# LPC11Axx register map
File version: 0.6
CPU: CM0 r0p0, little endian, no MPU, no FPU, 2 interrupt priority bits
Registers are 32-bit, read-write, reset 0x0 unless marked. A register's access mark holds for its fields unless they carry their own. Offsets are from the block's base; lines under a group give offsets from that group; [hi:lo] are bit positions; {n}, {i} and the like mark numbered series; 'fields as' and 'values as' point back to an identical list; <NAME> marks a mode.

## Memory map
0x40000000 I2C size 0x1000 — I2C-bus controller
0x40004000 WWDT size 0x1000 — Windowed Watchdog Timer (WWDT)
0x40008000 USART size 0x1000
0x4000C000 CT16B0 size 0x1000 — 16-bit counter/timers CT16B0/1
0x40010000 CT16B1 size 0x1000
0x40014000 CT32B0 size 0x1000 — 32-bit counter/timers CT32B0/1
0x40018000 CT32B1 size 0x1000
0x4001C000 ADC size 0x1000
0x40024000 DAC size 0x1000
0x40028000 CMP size 0x1000 — Comparator
0x4003C000 FMC size 0x1000 — Flash controller
0x40040000 SSP0 size 0x1000 — SSP/SPI
0x40044000 IOCON size 0x1000 — IOCON block
0x40048000 SYSCON size 0x1000 — System configuration
0x4004C000 GPIO_PIN_INT size 0x1000 — GPIO Modification
0x40058000 SSP1 size 0x1000
0x4005C000 GPIO_GROUP_INT0 size 0x1000 — GPIO group interrupt
0x40060000 GPIO_GROUP_INT1 size 0x1000
0x50000000 GPIO_PORT size 0x4000

## Interrupts
{n} PIN_INT{n} (GPIO_PIN_INT) (n=0..7)
8 GINT0 (GPIO_GROUP_INT0)
9 GINT1 (GPIO_GROUP_INT1)
10 CMP
11 DAC
12 RESERVED0 (SYSCON)
13 RESERVED1 (SYSCON)
14 SSP1
15 I2C
16 CT16B0
17 CT16B1
18 CT32B0
19 CT32B1
20 SSP0
21 USART
22 RESERVED2 (SYSCON)
23 RESERVED3 (SYSCON)
24 ADC
25 WDT (WWDT)
26 BOD (SYSCON)
27 FMC
28 RESERVED4 (SYSCON)
29 RESERVED5 (SYSCON)
30 RESERVED6 (SYSCON)
31 RESERVED7 (SYSCON)

## DAC
Base 0x40024000
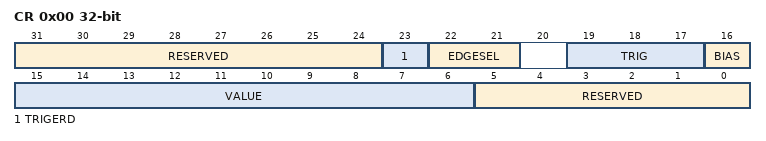
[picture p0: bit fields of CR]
0x00 CR — D/A control register
  [31:24] RESERVED — Reserved, user software should not write ones to reserved bits. The value read from a reserved bit is not defined.
  [23] TRIGERD — If the TRIG field (above) is non-zero, this bit is set when a conversion is triggered, and is cleared by any write to this register.
  [22:21] EDGESEL — For non-zero values of TRIG, this field selects when the conversion is triggered:
    0=FALLING (Falling edges); 1=RISINGs (Rising edges); 2=DUALEDGE (Both edges); 3=DUALEDGE (Both edges)
  [19:17] TRIG — The value written to this field determines whether conversion begins immediately after this register is written, or whether conversion is delayed until a selected event occurs.
    0=IMMEDIATE (Conversion begins when this register is written, and AOUT begins to change to the new voltage immediately. For all other values in this field, AOUT remains at its previous voltage until the selected event has occurred.); 1=COMPLEVELOUT (Conversion is triggered by the selected edge(s) on the analog comparator (level) output); 2=ATRG0EDGE (Conversion is triggered by the selected edge(s) on ATRG0.); 3=ATRG1EDGE (Conversion is triggered by the selected edge(s) on ATRG1.); 4=CT32B1_MAT0EDGE (Conversion is triggered by the selected edge(s) on CT32B1_MAT0 [2].); 5=CT32B1_MAT1EDGE (Conversion is triggered by the selected edge(s) on CT32B1_MAT1[2].); 6=CT16B1_MAT0EDGE (Conversion is triggered by the selected edge(s) on CT16B1_MAT0[2].); 7=CT16B1_MAT1EDGE (Conversion is triggered by the selected edge(s) on CT16B1_MAT1[2].)
  [16] BIAS — Settling time
    0=FAST (The settling time of the DAC is 1 us max, and the maximum current is 700 uA. This allows a maximum update rate of 1 MHz.); 1=SLOW (The settling time of the DAC is 2.5 us and the maximum current is 350 uA. This allows a maximum update rate of 400 kHz.)
  [15:6] VALUE — After the selected settling time after a conversion begins, the voltage on the AOUT pin (with respect to VSS) is VALUE x (V DD/1024).
  [5:0] RESERVED — Reserved, user software should not write ones to reserved bits. The value read from a reserved bit is not defined.
0x04 RESERVED
  [31:0] RESERVED — Reserved, user software should not write ones to reserved bits. The value read from a reserved bit is not defined.
